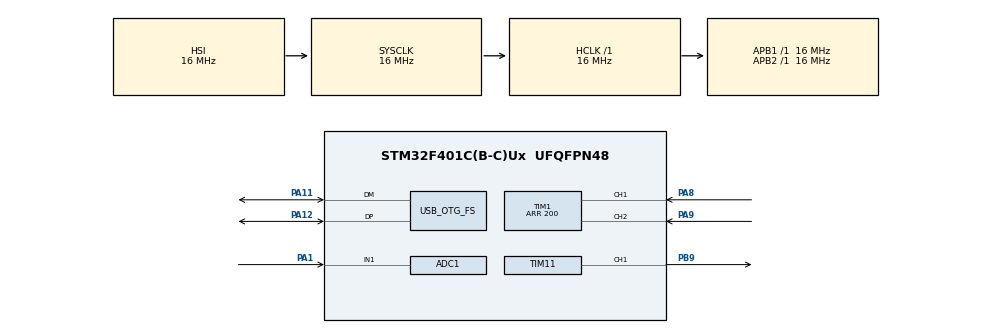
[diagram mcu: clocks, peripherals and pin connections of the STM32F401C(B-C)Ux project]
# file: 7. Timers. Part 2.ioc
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ADC1.Channel-0\#ChannelRegularConversion=ADC_CHANNEL_1
ADC1.ContinuousConvMode=DISABLE
ADC1.ExternalTrigConv=ADC_EXTERNALTRIGCONV_T3_TRGO
ADC1.NbrOfConversion=1
ADC1.NbrOfConversionFlag=1
ADC1.Rank-0\#ChannelRegularConversion=1
ADC1.SamplingTime-0\#ChannelRegularConversion=ADC_SAMPLETIME_3CYCLES
ADC1.master=1
Mcu.Family=STM32F4
Mcu.Name=STM32F401C(B-C)Ux
Mcu.Package=UFQFPN48
NVIC.ADC_IRQn=true\:2\:0\:true\:false\:true\:true\:true\:true
NVIC.OTG_FS_IRQn=true\:2\:0\:true\:false\:true\:false\:true\:true
NVIC.PriorityGroup=NVIC_PRIORITYGROUP_4
PA1.Signal=ADCx_IN1
PA11.Mode=Device_Only
PA11.Signal=USB_OTG_FS_DM
PA12.Mode=Device_Only
PA12.Signal=USB_OTG_FS_DP
PA13.Mode=Serial_Wire
PA13.Signal=SYS_JTMS-SWDIO
PA14.Mode=Serial_Wire
PA14.Signal=SYS_JTCK-SWCLK
PA8.Signal=S_TIM1_CH1
PA9.Signal=S_TIM1_CH2
PB9.Signal=S_TIM11_CH1
ProjectManager.HeapSize=0x200
ProjectManager.StackSize=0x400
ProjectManager.TargetToolchain=STM32CubeIDE
RCC.AHBFreq_Value=16000000
RCC.APB1Freq_Value=16000000
RCC.APB2Freq_Value=16000000
RCC.CortexFreq_Value=16000000
RCC.HSE_VALUE=25000000
RCC.HSI_VALUE=16000000
RCC.LSE_VALUE=32768
RCC.PLLSource=RCC_PLLSOURCE_HSI
RCC.PLLSourceVirtualString=RCC_PLLSOURCE_HSI
RCC.SYSCLKFreq_VALUE=16000000
RCC.VCOOutputFreq_Value=192000000
SH.ADCx_IN1.0=ADC1_IN1,IN1
SH.S_TIM11_CH1.0=TIM11_CH1,PWM Generation1 CH1
SH.S_TIM1_CH1.0=TIM1_CH1,Encoder_Interface
SH.S_TIM1_CH2.0=TIM1_CH2,Encoder_Interface
TIM1.Period=200
TIM11.Channel=TIM_CHANNEL_1
TIM11.Period=200-1
TIM11.Prescaler=16-1
TIM3.Period=10000
TIM3.Prescaler=16-1
TIM3.TIM_MasterOutputTrigger=TIM_TRGO_UPDATE
USB_DEVICE.CLASS_NAME_FS=CDC
USB_DEVICE.VirtualMode=Cdc
USB_DEVICE.VirtualModeFS=Cdc_FS
USB_OTG_FS.VirtualMode=Device_Only
VP_TIM11_VS_ClockSourceINT.Mode=Enable_Timer
VP_TIM3_VS_ClockSourceINT.Mode=Internal
VP_USB_DEVICE_VS_USB_DEVICE_CDC_FS.Mode=CDC_FS
board=custom

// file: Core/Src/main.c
/* USER CODE BEGIN Header */
/**
  ******************************************************************************
  * @file           : main.c
  * @brief          : Main program body
  ******************************************************************************
  * @attention
  *
  * Copyright (c) 2024 STMicroelectronics.
  * All rights reserved.
  *
  * This software is licensed under terms that can be found in the LICENSE file
  * in the root directory of this software component.
  * If no LICENSE file comes with this software, it is provided AS-IS.
  *
  ******************************************************************************
  */
/* USER CODE END Header */
#include "main.h"
#include "adc.h"
#include "tim.h"
#include "usb_device.h"
#include "gpio.h"

/* USER CODE BEGIN Includes */

#include "usbd_cdc_if.h"

/* USER CODE END Includes */

/* USER CODE BEGIN PD */

#define MAX_ADC 0xFFF

/* USER CODE END PD */

void SystemClock_Config(void);

int main(void)
{

  /* MCU Configuration--------------------------------------------------------*/

  /* Reset of all peripherals, Initializes the Flash interface and the Systick. */
  HAL_Init();

  /* Configure the system clock */
  SystemClock_Config();

  /* Initialize all configured peripherals */
  MX_GPIO_Init();
  MX_ADC1_Init();
  MX_TIM1_Init();
  MX_TIM3_Init();
  MX_TIM11_Init();
  MX_USB_DEVICE_Init();
  /* USER CODE BEGIN 2 */

  ADC1_Start_IT();
  TIM1_Encoder_Start();
  TIM11_PWM_Start();
  TIM3_Base_Start();

  /* USER CODE END 2 */

  /* Infinite loop */
  /* USER CODE BEGIN WHILE */
  while (1)
  {
	TIM11->CCR1 = TIM1->CNT;

    /* USER CODE END WHILE */

    /* USER CODE BEGIN 3 */
  }

  return 0;
  /* USER CODE END 3 */
}

void SystemClock_Config(void)
{
  RCC_OscInitTypeDef RCC_OscInitStruct = {0};
  RCC_ClkInitTypeDef RCC_ClkInitStruct = {0};

  /** Configure the main internal regulator output voltage
  */
  __HAL_RCC_PWR_CLK_ENABLE();
  __HAL_PWR_VOLTAGESCALING_CONFIG(PWR_REGULATOR_VOLTAGE_SCALE2);

  /** Initializes the RCC Oscillators according to the specified parameters
  * in the RCC_OscInitTypeDef structure.
  */
  RCC_OscInitStruct.OscillatorType = RCC_OSCILLATORTYPE_HSI;
  RCC_OscInitStruct.HSIState = RCC_HSI_ON;
  RCC_OscInitStruct.HSICalibrationValue = RCC_HSICALIBRATION_DEFAULT;
  RCC_OscInitStruct.PLL.PLLState = RCC_PLL_ON;
  RCC_OscInitStruct.PLL.PLLSource = RCC_PLLSOURCE_HSI;
  RCC_OscInitStruct.PLL.PLLM = 16;
  RCC_OscInitStruct.PLL.PLLN = 192;
  RCC_OscInitStruct.PLL.PLLP = RCC_PLLP_DIV2;
  RCC_OscInitStruct.PLL.PLLQ = 4;
  if (HAL_RCC_OscConfig(&RCC_OscInitStruct) != HAL_OK)
  {
    Error_Handler();
  }

  /** Initializes the CPU, AHB and APB buses clocks
  */
  RCC_ClkInitStruct.ClockType = RCC_CLOCKTYPE_HCLK|RCC_CLOCKTYPE_SYSCLK
                              |RCC_CLOCKTYPE_PCLK1|RCC_CLOCKTYPE_PCLK2;
  RCC_ClkInitStruct.SYSCLKSource = RCC_SYSCLKSOURCE_HSI;
  RCC_ClkInitStruct.AHBCLKDivider = RCC_SYSCLK_DIV1;
  RCC_ClkInitStruct.APB1CLKDivider = RCC_HCLK_DIV1;
  RCC_ClkInitStruct.APB2CLKDivider = RCC_HCLK_DIV1;

  if (HAL_RCC_ClockConfig(&RCC_ClkInitStruct, FLASH_LATENCY_0) != HAL_OK)
  {
    Error_Handler();
  }
}

/* USER CODE BEGIN 4 */

void HAL_ADC_ConvCpltCallback(ADC_HandleTypeDef* hadc)
{
	int volt = ADC1_GetValue() * 3300 / MAX_ADC;

	printf("%d\n", volt);
}

int _write(int file, char* buf, int len)
{
	CDC_Transmit_FS((uint8_t*)buf, len);
	return len;
}

/* USER CODE END 4 */

void Error_Handler(void)
{
  __disable_irq();
  while (1)
  {
  }
}
